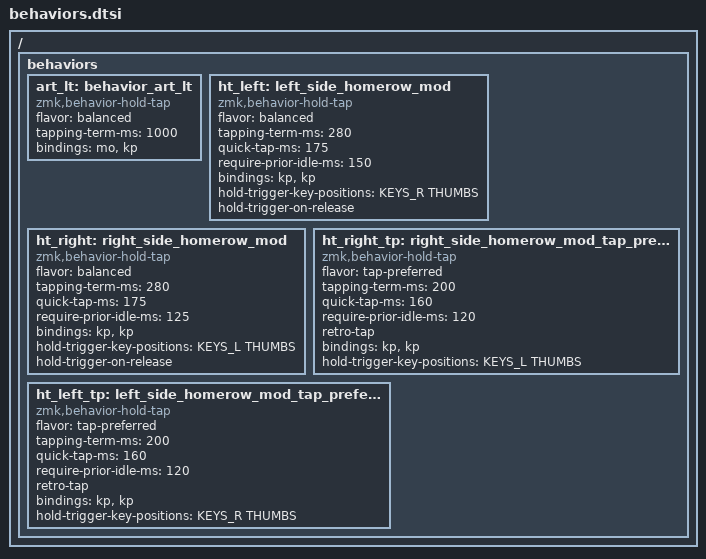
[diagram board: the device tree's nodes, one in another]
#define KEYS_L 0 1 2 3 4 5 12 13 14 15 16 17 24 25 26 27 28 29 36 37 38  // Left-hand keys.
#define KEYS_R 6 7 8 9 10 11 18 19 20 21 22 23 30 31 32 33 34 35 39 40  // Right-hand keys.
#define THUMBS 36 37 38 39 40  // Thumb keys.

/ {
    behaviors {
        // ht_num_func: homerow_mod {
        //     compatible = "zmk,behavior-hold-tap";
        //     #binding-cells = <2>;
        //     flavor = "tap-preferred";
        //     tapping-term-ms = <260>; // triggers the hold behavior when the tapping-term-ms has expired
        //     quick-tap-ms = <220>; // If you press a tapped hold-tap again within quick-tap-ms milliseconds of the first press, it will always trigger the tap behavior.
        //     require-prior-idle-ms = <185>; // like quick-tap-ms however it will apply for any non-modifier key pressed before it
        //     bindings = <&kp>, <&kp>;  // hold, tap
        // };


      art_lt: behavior_art_lt {
            compatible = "zmk,behavior-hold-tap";
            #binding-cells = <2>;
            flavor = "balanced";
            tapping-term-ms = <1000>;
            bindings = <&mo>, <&kp>;
        };

// Left-hand HRM
        ht_left: left_side_homerow_mod {
            compatible = "zmk,behavior-hold-tap";
            #binding-cells = <2>;
            flavor = "balanced";
            tapping-term-ms = <280>;
            quick-tap-ms = <175>;
            require-prior-idle-ms = <150>;
            bindings = <&kp>, <&kp>;
            hold-trigger-key-positions = <KEYS_R THUMBS>;
            hold-trigger-on-release;
        };

        // Right-hand HRM
        ht_right: right_side_homerow_mod {
            compatible = "zmk,behavior-hold-tap";
            #binding-cells = <2>;
            flavor = "balanced";
            tapping-term-ms = <280>;
            quick-tap-ms = <175>;
            require-prior-idle-ms = <125>;
            bindings = <&kp>, <&kp>;
            hold-trigger-key-positions = <KEYS_L THUMBS>;
            hold-trigger-on-release;
        };

        // Tap-biased right-hand HRM for fast-roll letters (used on positions 21/22).
        ht_right_tp: right_side_homerow_mod_tap_preferred {
            compatible = "zmk,behavior-hold-tap";
            #binding-cells = <2>;
            flavor = "tap-preferred";
            tapping-term-ms = <200>;
            quick-tap-ms = <160>;
            require-prior-idle-ms = <120>;
            retro-tap;
            bindings = <&kp>, <&kp>;
            hold-trigger-key-positions = <KEYS_L THUMBS>;
        };

        // Tap-biased left-hand HRM for fast-roll letter keys (used on A).
        ht_left_tp: left_side_homerow_mod_tap_preferred {
            compatible = "zmk,behavior-hold-tap";
            #binding-cells = <2>;
            flavor = "tap-preferred";
            tapping-term-ms = <200>;
            quick-tap-ms = <160>;
            require-prior-idle-ms = <120>;
            retro-tap;
            bindings = <&kp>, <&kp>;
            hold-trigger-key-positions = <KEYS_R THUMBS>;
        };



    };
};
